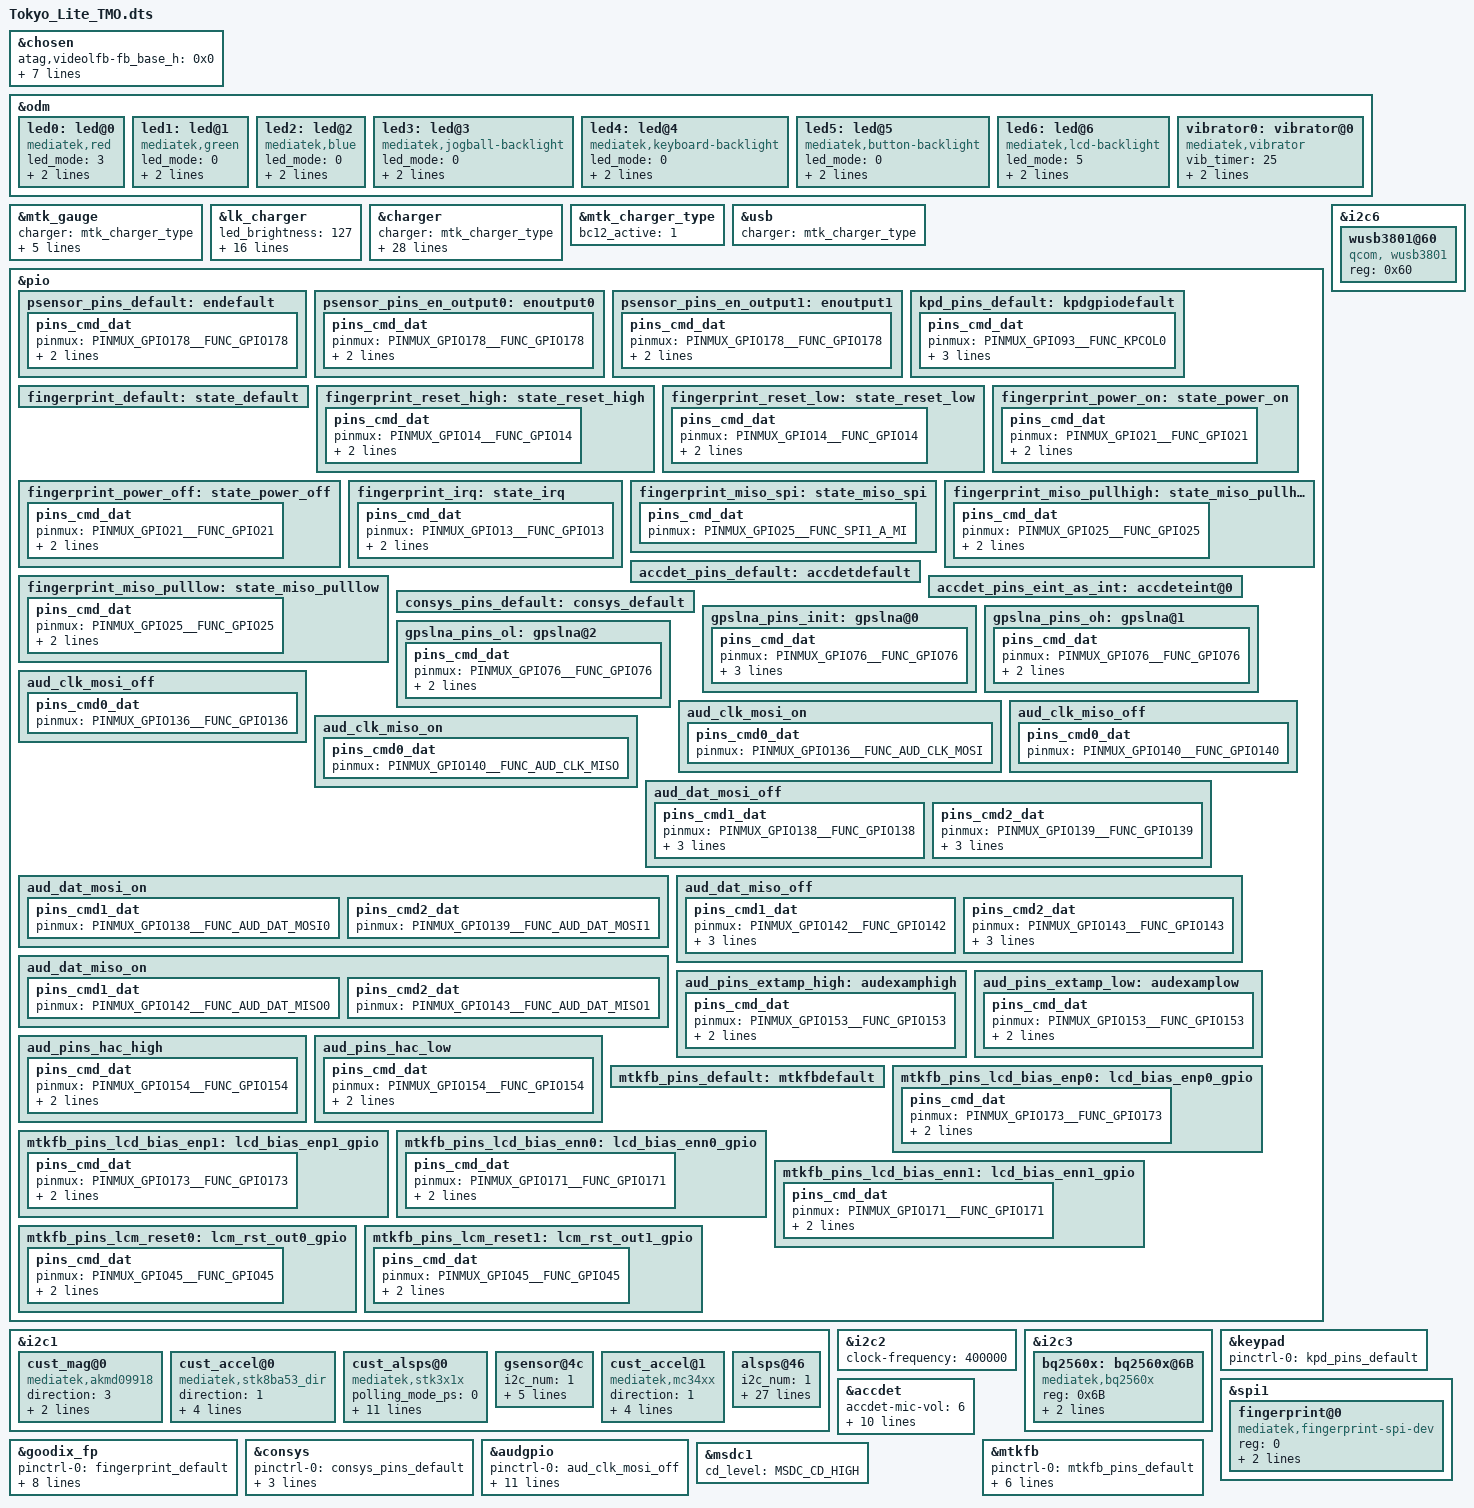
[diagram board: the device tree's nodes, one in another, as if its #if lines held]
// SPDX-License-Identifier: GPL-2.0+

#include <dt-bindings/interrupt-controller/arm-gic.h>
#include <dt-bindings/interrupt-controller/irq.h>
#include <dt-bindings/pinctrl/mt6761-pinfunc.h>
#include <dt-bindings/mmc/mt6761-msdc.h>
#include <dt-bindings/clock/mt6761-clk.h>
#include <dt-bindings/iio/mt635x-auxadc.h>

/dts-v1/;
/plugin/;

/* chosen */
&chosen {

	/* fpga may has no lk, we need to specify display info here */
	/* fb buffer is reserved using this dts by memory node above */
	atag,videolfb-fb_base_h = <0x0>;
	atag,videolfb-fb_base_l = <0x5e605000>;
	atag,videolfb-islcmfound = <1>;
	/* because no lk, so lcm is not inited */
	atag,videolfb-islcm_inited = <0>;
	atag,videolfb-fps= <6000>;
	atag,videolfb-vramSize= <0x017bb000>;
	atag,videolfb-lcmname= "nt35521_hd_dsi_vdo_truly_rt5081_drv";
};

&odm {
	led0:led@0 {
		compatible = "mediatek,red";
// change begin by TCT-cuiping.shi
		led_mode = <3>;
		data = <2>;
// change end by TCT-cuiping.shi
		pwm_config = <0 0 0 0 0>;
	};
	led1:led@1 {
		compatible = "mediatek,green";
		led_mode = <0>;
		data = <1>;
		pwm_config = <0 0 0 0 0>;
	};
	led2:led@2 {
		compatible = "mediatek,blue";
		led_mode = <0>;
		data = <1>;
		pwm_config = <0 0 0 0 0>;
	};
	led3:led@3 {
		compatible = "mediatek,jogball-backlight";
		led_mode = <0>;
		data = <1>;
		pwm_config = <0 0 0 0 0>;
	};
	led4:led@4 {
		compatible = "mediatek,keyboard-backlight";
		led_mode = <0>;
		data = <1>;
		pwm_config = <0 0 0 0 0>;
	};
	led5:led@5 {
		compatible = "mediatek,button-backlight";
		led_mode = <0>;
		data = <1>;
		pwm_config = <0 0 0 0 0>;
	};
	led6:led@6 {
		compatible = "mediatek,lcd-backlight";
		led_mode = <5>;
		data = <1>;
		pwm_config = <0 0 0 0 0>;
	};
	vibrator0:vibrator@0 {
		compatible = "mediatek,vibrator";
		vib_timer = <25>;
		vib_limit = <9>;
		vib_vol= <9>;
	};

};

&mtk_gauge {
	charger = <&mtk_charger_type>;

	io-channels = <&pmic_auxadc AUXADC_BAT_TEMP>,
			<&pmic_auxadc AUXADC_BATADC>,
			<&pmic_auxadc AUXADC_VBIF>,
			<&pmic_auxadc AUXADC_IMP>,
			<&auxadc 2>;
	io-channel-names = "pmic_battery_temp",
			"pmic_battery_voltage",
			"pmic_bif_voltage",
			"pmic_ptim_voltage",
			"batteryID-channel";
#if defined(TARGET_BUILD_MMITEST) || defined(TARGET_BUILD_CERTIFICATION) \
|| defined(TARGET_BUILD_GCF) || defined(DISABLE_TEMPERATURE_DETECTION_AND_THERMAL_POLICY)
        FIXED_BATTERY_TEMPERATURE = <25>;
#endif
};

/* Begin modified by dapeng.qiao for task 8997711 on 2020-03-16 */
/* Begin added by bitao.xiong for task-7884939 on 2019-07-04 */
&lk_charger {
        /delete-property/ enable_pe_plus;
        led_brightness = <127>;/* Modified by bitao.xiong for task-8281633 on 2019-08-23 */
        blinking_times = <6>;
        blinking_period = <1500>;

        /* charging current */
        usb_charger_current = <500000>;
        ac_charger_current = <500000>;
        ac_charger_input_current = <800000>;
        arch_32_bit = <0>;
        ac_charger_current_bq2560x = <2050000>;
        ac_charger_input_current_bq2560x  = <2050000>;
        ac_charger_current_sgm41511 = <2050000>;
        ac_charger_input_current_sgm41511  = <2050000>;
        non_std_ac_charger_current = <500000>;
        charging_host_charger_current = <500000>;
        /* Begin modified by hailong.chen for task 9535406 on 2020-06-22 */
        temp_t4_threshold = <55>;
        temp_t3_threshold = <42>;
        temp_t2_threshold = <11>;
        temp_t1_threshold = <0>;
        /* End modified by hailong.chen for task 9535406 on 2020-06-22 */
};

&charger {
	charger = <&mtk_charger_type>;
        /delete-property/ enable_pe_plus;
        /delete-property/ enable_pe_2;
        /delete-property/ enable_pe_3;
        /delete-property/ enable_pe_4;
        /delete-property/ enable_type_c;
        /delete-property/ enable_min_charge_temperature;
        /* Begin modified by bitao.xiong for task-8430235 on 2019-10-15 */
        ac_charger_input_current = <2200000>;
        ac_charger_current = <1980000>;
        /* End modified by bitao.xiong for task-8430235 on 2019-10-15 */
        battery_cv = <4400000>;
        chg_iterm_current =<180000>; /* Added by bitao.xiong for task-8430235 on 2019-12-09 */
        enable_sw_jeita;
        /* sw jeita */
        jeita_temp_above_t4_cv = <4100000>;
        jeita_temp_t3_to_t4_cv = <4100000>;
        jeita_temp_t2_to_t3_cv = <4390000>;
        jeita_temp_t1_to_t2_cv = <4390000>;
        jeita_temp_t0_to_t1_cv = <4390000>;
        jeita_temp_below_t0_cv = <4390000>;
        jeita_temp_t3_to_t4_cc = <1400000>; /* 45 - 55 Degree */
        jeita_temp_t1_to_t2_cc = <1400000>; /* 0 - 10 Degree */
        /* Begin modified by hailong.chen for task 9535406 on 2020-06-22 */
        temp_t4_thres= <55>;
        temp_t4_thres_minus_x_degree = <51>;
        temp_t3_thres = <42>;
        temp_t3_thres_minus_x_degree = <43>;
        temp_t2_thres = <11>;
        temp_t2_thres_plus_x_degree = <10>;
        temp_t1_thres = <1>;
        temp_t1_thres_plus_x_degree = <0>;
        temp_t0_thres = <1>;
        temp_t0_thres_plus_x_degree = <0>;
        temp_neg_10_thres = <1>;

        min_charge_temp = <1>;
        min_charge_temp_plus_x_degree = <1>;
        max_charge_temp = <55>;
        max_charge_temp_minus_x_degree = <51>;
        /* End modified by hailong.chen for task 9535406 on 2020-06-22 */
};
/* End added by bitao.xiong for task-7884939 on 2019-07-04 */
/* End modified by dapeng.qiao for task 8997711 on 2020-03-16 */

&mtk_charger_type {
	bc12_active = <1>;
};

&usb {
	charger = <&mtk_charger_type>;
};

/*Begin modified by hui.xiang for defect on 2019.7.9*/
&pio {
	psensor_pins_default: endefault {
		pins_cmd_dat {
			pinmux = <PINMUX_GPIO178__FUNC_GPIO178>;
			slew-rate = <1>;
			output-high;
		};
	};
	psensor_pins_en_output0: enoutput0 {
		pins_cmd_dat {
			pinmux = <PINMUX_GPIO178__FUNC_GPIO178>;
			slew-rate = <1>;
			output-low;
		};
	};
	psensor_pins_en_output1: enoutput1 {
		pins_cmd_dat {
			pinmux = <PINMUX_GPIO178__FUNC_GPIO178>;
			slew-rate = <1>;
			output-high;
		};
	};
};
&i2c1{
	cust_mag@0 {
		compatible		= "mediatek,akmd09918";
		/* i2c_num		= <1>; */
		/* i2c_addr		= <0x0C 0 0 0>; */
		direction		= <3>;
		power_id		= <0xffff>;
		power_vol		= <0>;
		/* is_batch_supported	= <0>; */
	};
	cust_accel@0 { 
        compatible = "mediatek,stk8ba53_dir";
        //i2c_num = <1>;
        direction = <1>;
        power_id = <0xffff>;
        power_vol = <0>;
        firlen = <0>;
        is_batch_supported = <0>;
	};
	cust_alsps@0 {
        compatible = "mediatek,stk3x1x";
        /*i2c_num = <1>;
        i2c_addr = <0x51 0 0 0>;*/
        polling_mode_ps = <0>;
        polling_mode_als = <1>;
        power_id = <0xffff>;
        power_vol = <0>;
        als_level = <0 328 861 1377 3125 7721 7767 12621 23062 28430 33274 47116 57694 57694 65535>;
        als_value = <0 133 304 502 1004 2005 3058 5005 8008 10010 12000 16000 20000 20000 20000 20000>;
        ps_threshold_high = <26>;
        ps_threshold_low = <21>;
        is_batch_supported_ps = <0>;
        is_batch_supported_als = <0>; 	
	};

	gsensor@4c {
                i2c_num = <1>;
                direction = <6>;
                power_id = <0xffff>;
                power_vol = <0>;
                firlen = <16>;
                is_batch_supported = <1>;
	};
	cust_accel@1 {
                compatible = "mediatek,mc34xx";
                //i2c_num       = <1>;
                direction = <1>;
                power_id = <0xffff>;
                power_vol = <0>;
                firlen = <0>;
                is_batch_supported = <0>;
	};
	alsps@46 {
                status = "okay";
                /* customization */
                i2c_num = <1>;
                i2c_addr = <0x46 0 0 0>;
                polling_mode_ps = <0>;
                polling_mode_als = <1>;
                power_id = <0xffff>;
                power_vol = <0>;
                als_level = <0 328 861 1377 3125 7721 7767 12621 23062 28430 33274 47116 57694 57694 65535>;
                als_value = <0 133 304 502 1004 2005 3058 5005 8008 10010 12000 16000 20000 20000 20000 20000>;
                ps_threshold_high       =  <65535>;
                ps_threshold_low        =  <0>;
                is_batch_supported_ps   = <0>;
                is_batch_supported_als  = <0>;
                stk,transmittance = <1000>;
                stk,state-reg = <0x00>;
                stk,psctrl-reg = <0x30>;
                stk,alsctrl-reg = <0x30>;
                stk,ledctrl-reg = <0x60>;
                stk,wait-reg = <0x0C>;
                stk,ps-thdh = <1000>;
                stk,ps-thdl = <900>;
                stk,mmi-thdh-limit = <5000>;
                stk,mmi-thdl-limit = <1>;
                stk,use-fir;
                pinctrl-names = "default","state_en_output0", "state_en_output1";
		pinctrl-0 = <&psensor_pins_default>;
		pinctrl-1 = <&psensor_pins_en_output0>;
		pinctrl-2 = <&psensor_pins_en_output1>;
	};

};
/*End modified by hui.xiang for defect on 2019.7.9*/

&i2c2 {
	#address-cells = <1>;
	#size-cells = <0>;
	clock-frequency = <400000>;
};

&i2c3 {
	/*bq25601:bq25601@6B{
		compatible = "mediatek,bq25601";
		reg = <0x6B>;
		status = "okay";
		charger_name = "primary_chg";
	};*/

	bq2560x: bq2560x@6B {
		compatible = "mediatek,bq2560x";
		reg = <0x6B>;
		charger_name = "primary_chg";
		alias_name = "bq2560x";
		status = "okay";
	};
};

&i2c6 {
	/* begin add wusb3801 */
	wusb3801@60 {
		compatible = "qcom, wusb3801";
		reg = <0x60>;
		status = "okay";
	};
	/* end */
};

&keypad {
	pinctrl-names = "default";
	pinctrl-0 = <&kpd_pins_default>;
};

&pio {
	kpd_pins_default: kpdgpiodefault {
		pins_cmd_dat {
			pinmux = <PINMUX_GPIO93__FUNC_KPCOL0>;
			bias-pull-up = <MTK_PUPD_SET_R1R0_10>;
			output-low;
			input-schmitt-enable;
		};
	};
};

/* Begin Modified by chunyang.zhou for 7821596 :enable headset accdet config */
/* FINGERPRINT start */
/* Begin to modified by yuduan.xie on 2019.07.31 for 8177729 */
&spi1 {
	#address-cells = <1>;
	#size-cells = <0>;
	fingerprint@0 {
		compatible = "mediatek,fingerprint-spi-dev";
		reg = <0>;
		spi-max-frequency = <12000000>;
		netlink-event = <31>;
		status = "okay";
	};
};
&goodix_fp{
	pinctrl-names = "fp_default", "fp_reset_high", "fp_reset_low", "fp_power_on", "fp_power_off", "fp_irq", "miso_spi", "miso_pullhigh", "miso_pulllow";
	pinctrl-0 = <&fingerprint_default>;
	pinctrl-1 = <&fingerprint_reset_high>;
	pinctrl-2 = <&fingerprint_reset_low>;
	pinctrl-3 = <&fingerprint_power_on>;
	pinctrl-4 = <&fingerprint_power_off>;
	pinctrl-5 = <&fingerprint_irq>;

	pinctrl-6 = <&fingerprint_miso_spi>;
	pinctrl-7 = <&fingerprint_miso_pullhigh>;
	pinctrl-8 = <&fingerprint_miso_pulllow>;

	status = "okay";
};

&pio {
	fingerprint_default: state_default {

	};

	fingerprint_reset_high: state_reset_high{
		pins_cmd_dat {
			pinmux = <PINMUX_GPIO14__FUNC_GPIO14>;
			slew-rate = <1>;
			output-high;
		};
	};

	fingerprint_reset_low: state_reset_low{
		pins_cmd_dat {
			pinmux = <PINMUX_GPIO14__FUNC_GPIO14>;
			slew-rate = <1>;
			output-low;
		};
	};

	fingerprint_power_on: state_power_on{
		pins_cmd_dat {
			pinmux = <PINMUX_GPIO21__FUNC_GPIO21>;
			slew-rate = <1>;
			output-high;
		};
	};

	fingerprint_power_off: state_power_off{
		pins_cmd_dat {
			pinmux = <PINMUX_GPIO21__FUNC_GPIO21>;
			slew-rate = <1>;
			output-low;
		};
	};

	fingerprint_irq: state_irq{
		pins_cmd_dat {
			pinmux = <PINMUX_GPIO13__FUNC_GPIO13>;
			slew-rate = <0>;
			bias-pull-down = <11>;
		};
	};

	fingerprint_miso_spi: state_miso_spi {
		pins_cmd_dat {
			pinmux = <PINMUX_GPIO25__FUNC_SPI1_A_MI>;
		};
	};
	fingerprint_miso_pullhigh: state_miso_pullhigh {
		pins_cmd_dat {
			pinmux = <PINMUX_GPIO25__FUNC_GPIO25>;
			slew-rate = <1>;
			output-high;
		};
	};
	fingerprint_miso_pulllow: state_miso_pulllow {
		pins_cmd_dat {
			pinmux = <PINMUX_GPIO25__FUNC_GPIO25>;
			slew-rate = <1>;
			output-low;
		};
	};
};
/* End to modified by yuduan.xie on 2019.07.31 for 8177729 */
/* FINGERPRINT end */

&accdet {
	/* accdet micbias voltage: 0x07,2.7v;0x05,2.5v;0x02,1.9v */
	accdet-mic-vol = <6>;
	headset-mode-setting = <0x500 0x500 1 0x1f0 0x1000 0x800 0x20 0x44>;
	accdet-plugout-debounce = <20>;
	/*1:ACC mode, 2:low cost without in bias, 6:low cost with in bias*/
	accdet-mic-mode = <1>;
	/* eint_level_trigger: 8,LEVEL_LOW(default);4,LEVEL_HIGH;others,LEVEL_LOW */
	headset-eint-level-pol = <8>;
	/*0--MD_MAX--UP_MAX--DW_MAX*/
	headset-three-key-threshold = <0 80 220 400>;
	headset-three-key-threshold-CDD = <0 121 192 600>;
	/*0--MD_MAX--VOICE_MAX--UP_MAX--DW_MAX*/
	headset-four-key-threshold = <0 58 121 192 400>;
	pinctrl-names = "default", "state_eint_as_int";
	pinctrl-0 = <&accdet_pins_default>;
	pinctrl-1 = <&accdet_pins_eint_as_int>;
	status = "okay";
};
/* End Modified by chunyang.zhou for 7821596 :enable headset accdet config */
&pio {
	accdet_pins_default: accdetdefault {
	};
	accdet_pins_eint_as_int: accdeteint@0 {
//Begin modify by lanying.he for task 8997872 on 2020/03/16
//End modify by lanying.he for task 8997872 on 2020/03/16
	};
};

/* CONSYS GPIO standardization */
/* Added By suqi.liu for defect 10430270 : Add tokyo tmo R GPS config */
&pio {
	consys_pins_default: consys_default {
	};
	gpslna_pins_init: gpslna@0 {
		pins_cmd_dat {
			pinmux = <PINMUX_GPIO76__FUNC_GPIO76>;
			slew-rate = <0>;
			bias-disable;
			output-low;
		};
	};
	gpslna_pins_oh: gpslna@1 {
		pins_cmd_dat {
			pinmux = <PINMUX_GPIO76__FUNC_GPIO76>;
			slew-rate = <1>;
			output-high;
		};
	};
	gpslna_pins_ol: gpslna@2 {
		pins_cmd_dat {
			pinmux = <PINMUX_GPIO76__FUNC_GPIO76>;
			slew-rate = <1>;
			output-low;
		};
	};
};
&consys {
	pinctrl-names = "default", "gps_lna_state_init",
		"gps_lna_state_oh", "gps_lna_state_ol";
	pinctrl-0 = <&consys_pins_default>;
	pinctrl-1 = <&gpslna_pins_init>;
	pinctrl-2 = <&gpslna_pins_oh>;
	pinctrl-3 = <&gpslna_pins_ol>;
	status = "okay";
};
/* Ended By suqi.liu for defect 10430270 : Add tokyo tmo R GPS config */
/* CONSYS end */

/* AUDIO GPIO standardization */
/* Added By chunyang.zhou for task 7821596 : Add tokyo & soual audio config */
&audgpio {
	pinctrl-names = "aud_clk_mosi_off",
			"aud_clk_mosi_on",
			"aud_clk_miso_off",
			"aud_clk_miso_on",
			"aud_dat_mosi_off",
			"aud_dat_mosi_on",
			"aud_dat_miso_off",
			"aud_dat_miso_on",
			"extamp-pullhigh",
			"extamp-pulllow",
			"hac-pullhigh",
			"hac-pulllow";
	pinctrl-0 = <&aud_clk_mosi_off>;
	pinctrl-1 = <&aud_clk_mosi_on>;
	pinctrl-2 = <&aud_clk_miso_off>;
	pinctrl-3 = <&aud_clk_miso_on>;
	pinctrl-4 = <&aud_dat_mosi_off>;
	pinctrl-5 = <&aud_dat_mosi_on>;
	pinctrl-6 = <&aud_dat_miso_off>;
	pinctrl-7 = <&aud_dat_miso_on>;
	pinctrl-8 = <&aud_pins_extamp_high>;
	pinctrl-9 = <&aud_pins_extamp_low>;
	pinctrl-10 = <&aud_pins_hac_high>;
	pinctrl-11 = <&aud_pins_hac_low>;
	status = "okay";
};

&pio {
	aud_clk_mosi_off: aud_clk_mosi_off {
		pins_cmd0_dat {
			pinmux = <PINMUX_GPIO136__FUNC_GPIO136>;
		};
	};

	aud_clk_mosi_on: aud_clk_mosi_on {
		pins_cmd0_dat {
			pinmux = <PINMUX_GPIO136__FUNC_AUD_CLK_MOSI>;
		};
	};

	aud_clk_miso_off: aud_clk_miso_off {
		pins_cmd0_dat {
			pinmux = <PINMUX_GPIO140__FUNC_GPIO140>;
		};
	};

	aud_clk_miso_on: aud_clk_miso_on {
		pins_cmd0_dat {
			pinmux = <PINMUX_GPIO140__FUNC_AUD_CLK_MISO>;
		};
	};

	aud_dat_mosi_off: aud_dat_mosi_off {
		pins_cmd1_dat {
			pinmux = <PINMUX_GPIO138__FUNC_GPIO138>;
			input-enable;
			slew-rate = <0>;
			bias-disable;
		};
		pins_cmd2_dat {
			pinmux = <PINMUX_GPIO139__FUNC_GPIO139>;
			input-enable;
			slew-rate = <0>;
			bias-disable;
		};
	};

	aud_dat_mosi_on: aud_dat_mosi_on {
		pins_cmd1_dat {
			pinmux = <PINMUX_GPIO138__FUNC_AUD_DAT_MOSI0>;
		};
		pins_cmd2_dat {
			pinmux = <PINMUX_GPIO139__FUNC_AUD_DAT_MOSI1>;
		};
	};

	aud_dat_miso_off: aud_dat_miso_off {
		pins_cmd1_dat {
			pinmux = <PINMUX_GPIO142__FUNC_GPIO142>;
			input-enable;
			slew-rate = <0>;
			bias-disable;
		};
		pins_cmd2_dat {
			pinmux = <PINMUX_GPIO143__FUNC_GPIO143>;
			input-enable;
			slew-rate = <0>;
			bias-disable;
		};
	};

	aud_dat_miso_on: aud_dat_miso_on {
		pins_cmd1_dat {
			pinmux = <PINMUX_GPIO142__FUNC_AUD_DAT_MISO0>;
		};
		pins_cmd2_dat {
			pinmux = <PINMUX_GPIO143__FUNC_AUD_DAT_MISO1>;
		};
	};

	aud_pins_extamp_high: audexamphigh {
		pins_cmd_dat {
			pinmux = <PINMUX_GPIO153__FUNC_GPIO153>;
			slew-rate = <1>;
			output-high;
		};
	};

	aud_pins_extamp_low: audexamplow {
		pins_cmd_dat {
			pinmux = <PINMUX_GPIO153__FUNC_GPIO153>;
			slew-rate = <1>;
			output-low;
		};
	};

	aud_pins_hac_high: aud_pins_hac_high {
		pins_cmd_dat {
			pinmux = <PINMUX_GPIO154__FUNC_GPIO154>;
			slew-rate = <1>;
			output-high;
		};
	};

	aud_pins_hac_low: aud_pins_hac_low {
		pins_cmd_dat {
			pinmux = <PINMUX_GPIO154__FUNC_GPIO154>;
			slew-rate = <1>;
			output-low;
		};
	};
};
/* End By chunyang.zhou for task 7821596 : Add tokyo & soual audio config */
/* AUDIO end */

&mtkfb {
	pinctrl-names = "default", "lcd_bias_enp0_gpio", "lcd_bias_enp1_gpio","lcd_bias_enn0_gpio", "lcd_bias_enn1_gpio", "lcm_rst_out0_gpio", "lcm_rst_out1_gpio";
	pinctrl-0 = <&mtkfb_pins_default>;
	pinctrl-1 = <&mtkfb_pins_lcd_bias_enp0>;
	pinctrl-2 = <&mtkfb_pins_lcd_bias_enp1>;
	pinctrl-3 = <&mtkfb_pins_lcd_bias_enn0>; 
	pinctrl-4 = <&mtkfb_pins_lcd_bias_enn1>; 
	pinctrl-5 = <&mtkfb_pins_lcm_reset0>; 
 	pinctrl-6 = <&mtkfb_pins_lcm_reset1>;
	status = "okay";
};
&pio {
	mtkfb_pins_default: mtkfbdefault {
	};

	mtkfb_pins_lcd_bias_enp0: lcd_bias_enp0_gpio {
		pins_cmd_dat {
			pinmux = <PINMUX_GPIO173__FUNC_GPIO173>;
			slew-rate = <1>;
			output-low;
		};
	};

	mtkfb_pins_lcd_bias_enp1: lcd_bias_enp1_gpio {
		pins_cmd_dat {
			pinmux = <PINMUX_GPIO173__FUNC_GPIO173>;
			slew-rate = <1>;
			output-high;
		};
	};

	mtkfb_pins_lcd_bias_enn0: lcd_bias_enn0_gpio {
                   pins_cmd_dat {
                            pinmux = <PINMUX_GPIO171__FUNC_GPIO171>;
                            slew-rate = <1>;
                            output-low;
                   };
         };

         mtkfb_pins_lcd_bias_enn1: lcd_bias_enn1_gpio {
                   pins_cmd_dat {
                            pinmux = <PINMUX_GPIO171__FUNC_GPIO171>;
                            slew-rate = <1>;
                            output-high;
                   };
         };

//add begin by yusen.ke.sz for fix reset error on 20190605
 	mtkfb_pins_lcm_reset0: lcm_rst_out0_gpio {
 		pins_cmd_dat {
 			pinmux = <PINMUX_GPIO45__FUNC_GPIO45>;
 			slew-rate = <1>;
 			output-low;
 		};
 	};
 
 	mtkfb_pins_lcm_reset1: lcm_rst_out1_gpio {
 		pins_cmd_dat {
 			pinmux = <PINMUX_GPIO45__FUNC_GPIO45>;
 			slew-rate = <1>;
 			output-high;
 		};
 	};
 //add end by yusen.ke.sz for fix reset error on 20190605


};

//Add-start by baiwei.peng for SDcard detect on 2020/09/16
&msdc1 {
        cd_level = /bits/ 8 <MSDC_CD_HIGH>;
};
//Add-end by baiwei.peng for SDcard detect on 2020/09/16

#include <Tokyo_Lite_TMO/cust.dtsi>
//#include "cust_mt6761_camera.dtsi"
#include "cust_mt6761_Tokyo_Lite_TMO_camera.dtsi" // lihao for  Tokyo_Lite_TMO 20200910
#include "cust_mt6761_Tokyo_Lite_TMO_touch.dtsi"
#include "bat_setting/TOKYO_LITE_TMO_mt6761_battery_prop.dtsi"
/*End of this file, DO NOT ADD ANYTHING HERE*/
